# STM32WL3R register map
File version: 1.0
CPU: CM0+ r0p0, little endian, MPU, no FPU, 4 interrupt priority bits
Registers are 32-bit, read-write, reset 0x0 unless marked. A register's access mark holds for its fields unless they carry their own. Offsets are from the block's base; [hi:lo] are bit positions.

## RCC — RCC address block description
Base 0x48400000
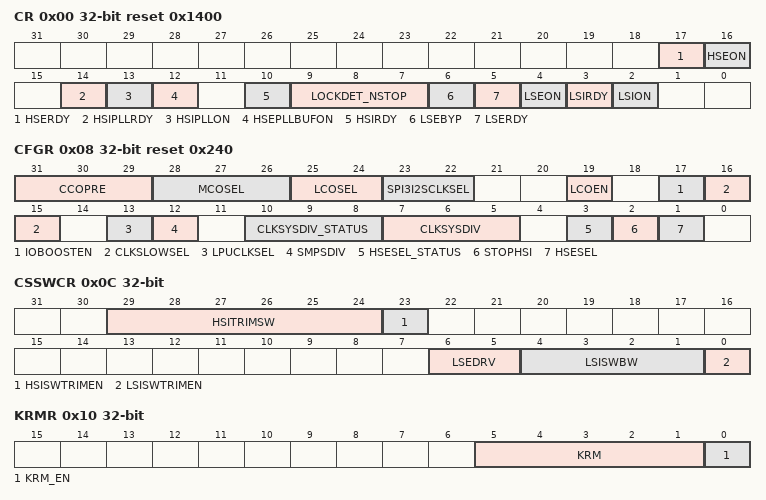
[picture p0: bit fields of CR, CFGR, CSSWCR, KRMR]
0x00 CR reset 0x1400
  [17] HSERDY ro — External High Speed Clock ready flag.
  [16] HSEON — External High Speed Clock enable.
  [14] HSIPLLRDY ro — Internal High Speed Clock PLL ready flag.
  [13] HSIPLLON — Internal High Speed Clock PLL enable
  [12] HSEPLLBUFON — External High Speed Clock Buffer for PLL RF enable.
  [10] HSIRDY ro — Internal High Speed clock ready flag.
  [9:7] LOCKDET_NSTOP — Lock detector Nstop value
  [6] LSEBYP — External Low Speed Clock bypass.
  [5] LSERDY ro — External Low Speed Clock ready flag.
  [4] LSEON — External Low Speed Clock enable.
  [3] LSIRDY ro — Internal Low Speed oscillator Ready
  [2] LSION — Internal Low Speed oscillator enable
0x08 CFGR reset 0x240
  [31:29] CCOPRE — Configurable Clock Output Prescaler.
  [28:26] MCOSEL — Main Configurable Clock Output Selection.
  [25:24] LCOSEL — Low speed Configurable Clock Output Selection.
  [23:22] SPI3I2SCLKSEL — SPI3I2SCLKSEL: Selection of I2S clock for SPI3 IP.
  [19] LCOEN — LCOEN: LCO enable on PA10 also in deepstop.
  [17] IOBOOSTEN — IOBOOSTEN: IO BOOSTER enable
  [16:15] CLKSLOWSEL — slow clock source selection
  [13] LPUCLKSEL — LPUCLKSEL: Selection of LPUART clock
  [12] SMPSDIV — SMPS clock prescaling factor to generate 4MHz or 8MHz
  [10:8] CLKSYSDIV_STATUS ro — system clock frequency selection status
  [7:5] CLKSYSDIV — system clock frequency selection request
  [3] HSESEL_STATUS ro — Clock source selection Status
  [2] STOPHSI — Stop HSI clock source request
  [1] HSESEL — Clock source selection request:
0x0C CSSWCR
  [29:24] HSITRIMSW — High Speed Internal clock trimming value to set by SW.
  [23] HSISWTRIMEN — High Speed oscillator trimming by SW enable
  [6:5] LSEDRV — Maximum Crystal gm for Low Speed External XO
  [4:1] LSISWBW — Low Speed Internal clock trimming value to set by SW
  [0] LSISWTRIMEN — Low Speed oscillator trimming by SW enable
0x10 KRMR
  [5:1] KRM — KRM[4:0] :SMPS clock dividing Ratio (CLK_SPMS_KRM frequency= CLK_ROOT frequency
  [0] KRM_EN — KRM_EN: Variable rate multiplier Enable
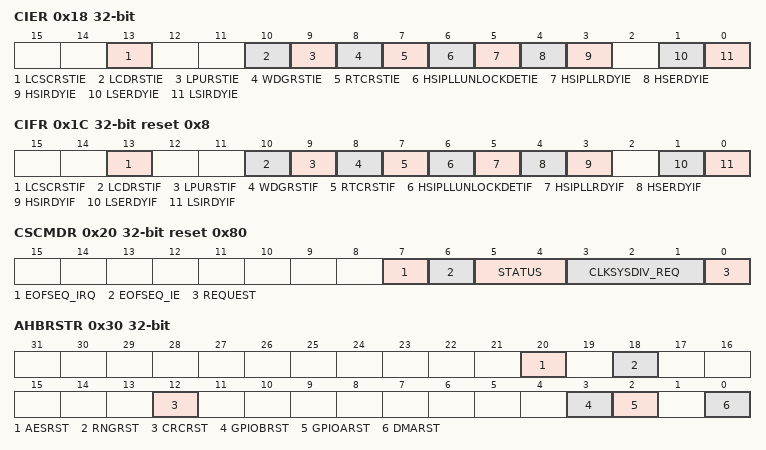
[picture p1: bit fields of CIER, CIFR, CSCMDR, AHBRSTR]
0x18 CIER
  [13] LCSCRSTIE — LCSCRSTIE: LCSC reset release interrupt enable.
  [10] LCDRSTIE — LCDRSTIE: LCD reset end Interrupt Enable.
  [9] LPURSTIE — LPURSTIE: LPUART reset end Interrupt Enable.
  [8] WDGRSTIE — WDGRSTIE: Watchdog reset end Interrupt Enable.
  [7] RTCRSTIE — RTCRSTIE: RTC reset end Interrupt Enable.
  [6] HSIPLLUNLOCKDETIE — HSIPLLUNLOCKDETIE: HSI PLL unlock detection Interrupt Enable.
  [5] HSIPLLRDYIE — HSI PLL Ready Interrupt Enable.
  [4] HSERDYIE — HSE Ready Interrupt Enable
  [3] HSIRDYIE — HSI Ready Interrupt Enable.
  [1] LSERDYIE — LSE Ready Interrupt Enable.
  [0] LSIRDYIE — LSI Ready Interrupt Enable.
0x1C CIFR reset 0x8
  [13] LCSCRSTIF — LCSC reset end Interrupt Flag.
  [10] LCDRSTIF — LCD reset end Interrupt Flag.
  [9] LPURSTIF — LPUART reset end Interrupt Flag.
  [8] WDGRSTIF — WDG reset end Interrupt Flag.
  [7] RTCRSTIF — RTC reset end Interrupt Flag.
  [6] HSIPLLUNLOCKDETIF — HSIPLLUNLOCKDETIF: HSI PLL unlock detection Interrupt Flag.
  [5] HSIPLLRDYIF — HSI PLL Ready Interrupt Flag.
  [4] HSERDYIF — HSE Ready Interrupt Flag.
  [3] HSIRDYIF — HSI Ready Interrupt Flag.
  [1] LSERDYIF — LSE Ready Interrupt Flag.
  [0] LSIRDYIF — LSI Ready Interrupt flag
0x20 CSCMDR reset 0x80
  [7] EOFSEQ_IRQ — End of Sequence flag
  [6] EOFSEQ_IE — End of sequence Interrupt Enable.
  [5:4] STATUS ro — Status of clock switch sequence
  [3:1] CLKSYSDIV_REQ — system clock frequency selection request
  [0] REQUEST — Request for system clock switching
0x30 AHBRSTR
  [20] AESRST — AES reset
  [18] RNGRST — RNG reset
  [12] CRCRST — CRC reset
  [3] GPIOBRST — GPIOB reset
  [2] GPIOARST — GPIOA reset
  [0] DMARST — DMA and DMAMUX reset
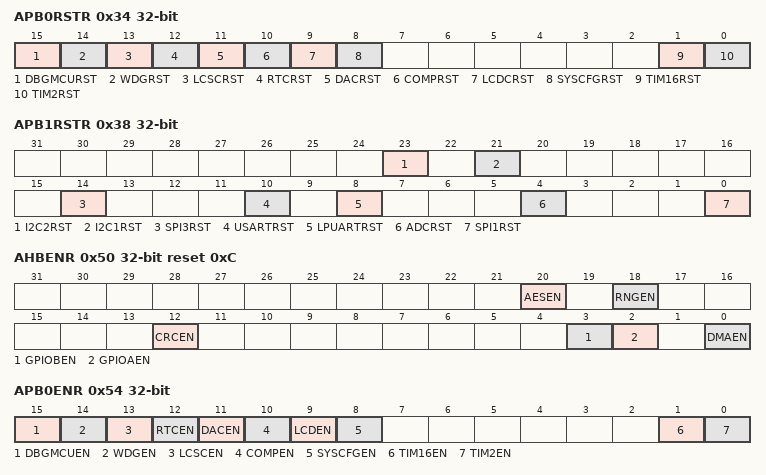
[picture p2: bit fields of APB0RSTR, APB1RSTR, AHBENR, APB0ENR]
0x34 APB0RSTR
  [15] DBGMCURST — DBGMCURST: DBGMCU reset.
  [14] WDGRST — WDGRST: Watchdog reset.
  [13] LCSCRST — LCSCRST: LCSC reset.
  [12] RTCRST — RTCRST: RTC reset.
  [11] DACRST — DACRST: DAC reset.
  [10] COMPRST — COMPRST: COMP reset.
  [9] LCDCRST — LCDCRST: LCD controller reset.
  [8] SYSCFGRST — SYSCFGRST: system controller reset.
  [1] TIM16RST — TIM16RST: TIM16 reset.
  [0] TIM2RST — TIM2RST: TIM2 reset.
0x38 APB1RSTR
  [23] I2C2RST — I2C2 reset
  [21] I2C1RST — I2C1 reset
  [14] SPI3RST — SPI3 reset
  [10] USARTRST — USART reset
  [8] LPUARTRST — LPUART reset
  [4] ADCRST — ADC reset for Aux-ADC IP
  [0] SPI1RST — SPI1 reset
0x40 APB2RSTR
  [0] MRSUBGRST — Radio MRSUBG reset.
0x50 AHBENR reset 0xC
  [20] AESEN — AESEN: AES clock enable.
  [18] RNGEN — RNG clock enable
  [12] CRCEN — CRC enable
  [3] GPIOBEN — GPIOB enable.
  [2] GPIOAEN — GPIOA enable.
  [0] DMAEN — DMA and DMAMUX enable
0x54 APB0ENR
  [15] DBGMCUEN — DBG MCU clock enable.
  [14] WDGEN — Watchdog clock enable.
  [13] LCSCEN — LCSC clock enable.
  [12] RTCEN — RTC clock enable
  [11] DACEN — DAC clock enable
  [10] COMPEN — COMP clock enable
  [9] LCDEN — LCD clock enable
  [8] SYSCFGEN — SYSTEM CONFIG clock enable
  [1] TIM16EN — TIM16: Advanced Timer clock enable
  [0] TIM2EN — TIM2: Advanced Timer clock enable
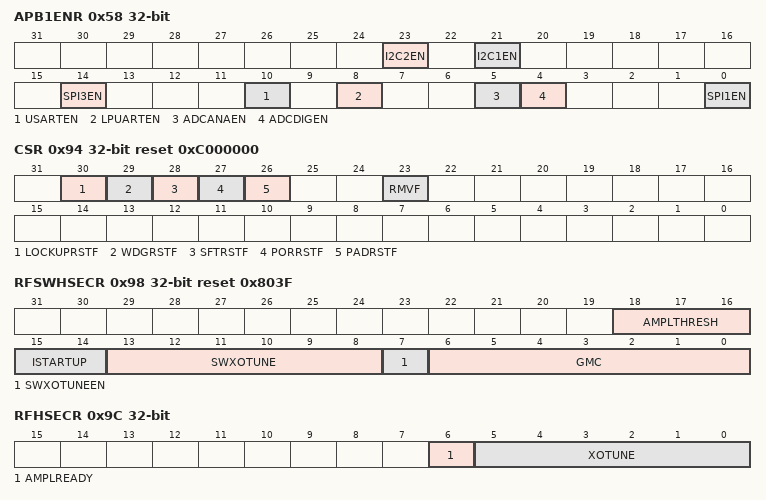
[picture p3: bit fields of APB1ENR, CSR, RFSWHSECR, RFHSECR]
0x58 APB1ENR
  [23] I2C2EN — I2C2 clock enable
  [21] I2C1EN — I2C1 clock enable
  [14] SPI3EN — SPI3 clock enable
  [10] USARTEN — USART clock enable
  [8] LPUARTEN — LPUART clock enable
  [5] ADCANAEN — ADC clock enable for Aux-ADC analog clock
  [4] ADCDIGEN — AUXADC clock enable for Aux-ADC digital clock
  [0] SPI1EN — SPI1 clock enable
0x60 APB2ENR
  [0] MRSUBGEN — MRSUBG clock enable.
0x94 CSR reset 0xC000000
  [30] LOCKUPRSTF ro — LOCK UP reset flag from CM0
  [29] WDGRSTF ro — Watchdog reset flag
  [28] SFTRSTF ro — Software reset flag
  [27] PORRSTF ro — POWER reset flag
  [26] PADRSTF ro — SYSTEM reset flag
  [23] RMVF wo — Remove reset flag
0x98 RFSWHSECR reset 0x803F
  [18:16] AMPLTHRESH — RF-HSE Amplitude Control threshold
  [15:14] ISTARTUP — RF-HSE Startup current
  [13:8] SWXOTUNE — RF-HSE capacitor bank tuning value by SW
  [7] SWXOTUNEEN — RF-HSE capacitor bank tuning by SW enable
  [6:0] GMC — GMC[6:5]: High speed external XO current control reference
0x9C RFHSECR ro
  [6] AMPLREADY — RF-HSE Amplitude Control Ready output
  [5:0] XOTUNE — RF-HSE capacitor bank tuning
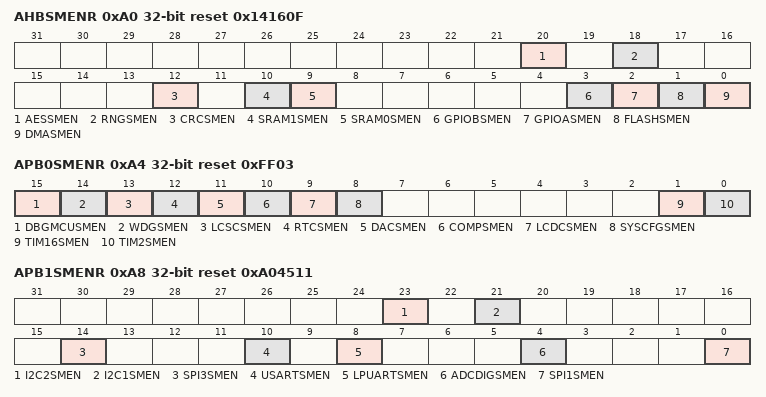
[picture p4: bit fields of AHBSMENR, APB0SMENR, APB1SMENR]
0xA0 AHBSMENR reset 0x14160F
  [20] AESSMEN — AES bus clock enable during Sleep mode bit
  [18] RNGSMEN — RNG bus clock enable during Sleep mode bit
  [12] CRCSMEN — CRC clock enable during Sleep mode bit
  [10] SRAM1SMEN — SRAM1 clock enable during Sleep mode bit
  [9] SRAM0SMEN — SRAM0 clock enable during Sleep mode bit
  [3] GPIOBSMEN — GPIOB clock enable during Sleep mode bit
  [2] GPIOASMEN — GPIOA clock enable during Sleep mode bit
  [1] FLASHSMEN — Flash clocks enable during Flash Sleep PD and CPU Sleep mode bit
  [0] DMASMEN — DMA clock enable during Sleep mode bit
0xA4 APB0SMENR reset 0xFF03
  [15] DBGMCUSMEN — DBGMCU clock enable during Sleep mode bit
  [14] WDGSMEN — WDG clock enable during Sleep mode bit
  [13] LCSCSMEN — LCSC bus clock enable during Sleep mode bit
  [12] RTCSMEN — RTC bus clock enable during Sleep mode bit
  [11] DACSMEN — DAC bus clock enable during Sleep mode bit
  [10] COMPSMEN — COMP bus clock enable during Sleep mode bit
  [9] LCDCSMEN — LCDC bus clock enable during Sleep mode bit
  [8] SYSCFGSMEN — SYSCFG bus clock enable during Sleep mode bit
  [1] TIM16SMEN — TIM16 bus clock enable during Sleep mode bit
  [0] TIM2SMEN — TIM2 bus clock enable during Sleep mode bit
0xA8 APB1SMENR reset 0xA04511
  [23] I2C2SMEN — I2C2 clock enable during Sleep mode bit
  [21] I2C1SMEN — I2C1 clock enable during Sleep mode bit
  [14] SPI3SMEN — SPI3 bus clock enable during Sleep mode bit
  [10] USARTSMEN — USART bus clock enable during Sleep mode bit
  [8] LPUARTSMEN — LPUART bus clock enable during Sleep mode bit
  [4] ADCDIGSMEN — ADCDIG bus clock enable during Sleep mode bit
  [0] SPI1SMEN — SPI1 bus clock enable during Sleep mode bit
